AUTOSAR XML (schema 00046)
package /ComponentTypes
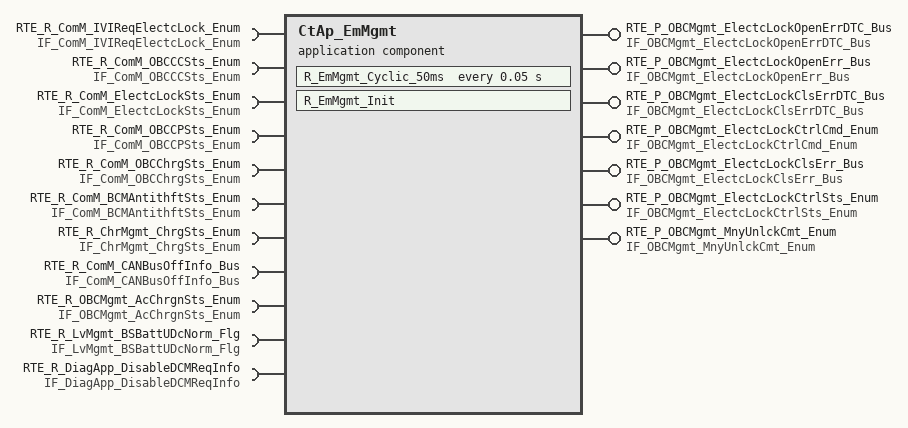
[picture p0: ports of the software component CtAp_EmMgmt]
  application sw component type CtAp_EmMgmt
    5 x provide port:
      RTE_P_OBCMgmt_ElectcLockOpenErrDTC_Bus: nonqueued-sender-com-spec{data-element=tec_OBCMgmt_ElectcLockOpenErrDTC_Bus, init-value=fields=[OBCMgmt_MonStatElectcLockOpenErrDTC:0, OBCMgmt_MonResElectcLockOpenErrDTC:0, OBCMgmt_ErrStatElectcLockOpenErrDTC:0, OBCMgmt_ErrResElectcLockOpenErrDTC:0]}, provided-interface=IF_OBCMgmt_ElectcLockOpenErrDTC_Bus
      RTE_P_OBCMgmt_ElectcLockOpenErr_Bus: nonqueued-sender-com-spec{data-element=tec_OBCMgmt_ElectcLockOpenErr_Bus, init-value=fields=[OBCMgmt_MonStatElectcLockOpenErr:0, OBCMgmt_MonResElectcLockOpenErr:0, OBCMgmt_ErrStatElectcLockOpenErr:0, OBCMgmt_ErrResElectcLockOpenErr:0]}, provided-interface=IF_OBCMgmt_ElectcLockOpenErr_Bus
      RTE_P_OBCMgmt_ElectcLockClsErrDTC_Bus: nonqueued-sender-com-spec{data-element=tec_OBCMgmt_ElectcLockClsErrDTC_Bus, init-value=fields=[OBCMgmt_MonStatElectcLockClsErrDTC:0, OBCMgmt_MonResElectcLockClsErrDTC:0, OBCMgmt_ErrStatElectcLockClsErrDTC:0, OBCMgmt_ErrResElectcLockClsErrDTC:0]}, provided-interface=IF_OBCMgmt_ElectcLockClsErrDTC_Bus
      RTE_P_OBCMgmt_ElectcLockCtrlCmd_Enum: nonqueued-sender-com-spec{data-element=tec_OBCMgmt_ElectcLockCtrlCmd_Enum, init-value=0}, provided-interface=IF_OBCMgmt_ElectcLockCtrlCmd_Enum
      RTE_P_OBCMgmt_ElectcLockClsErr_Bus: nonqueued-sender-com-spec{data-element=tec_OBCMgmt_ElectcLockClsErr_Bus, init-value=fields=[OBCMgmt_MonStatElectcLockClsErr:0, OBCMgmt_MonResElectcLockClsErr:0, OBCMgmt_ErrStatElectcLockClsErr:0, OBCMgmt_ErrResElectcLockClsErr:0]}, provided-interface=IF_OBCMgmt_ElectcLockClsErr_Bus
    require port RTE_R_ComM_IVIReqElectcLock_Enum: nonqueued-receiver-com-spec{data-element=tec_ComM_IVIReqElectcLock_Enum, filter=data-filter-type=ALWAYS, init-value=0}, required-interface=IF_ComM_IVIReqElectcLock_Enum
    provide port RTE_P_OBCMgmt_ElectcLockCtrlSts_Enum: nonqueued-sender-com-spec{data-element=tec_OBCMgmt_ElectcLockCtrlSts_Enum, init-value=0}, provided-interface=IF_OBCMgmt_ElectcLockCtrlSts_Enum
    require port RTE_R_ComM_OBCCCSts_Enum: nonqueued-receiver-com-spec{data-element=tec_ComM_OBCCCSts_Enum, filter=data-filter-type=ALWAYS, init-value=0}, required-interface=IF_ComM_OBCCCSts_Enum
    require port RTE_R_ComM_ElectcLockSts_Enum: nonqueued-receiver-com-spec{data-element=tec_ComM_ElectcLockSts_Enum, filter=data-filter-type=ALWAYS, init-value=0}, required-interface=IF_ComM_ElectcLockSts_Enum
    require port RTE_R_ComM_OBCCPSts_Enum: nonqueued-receiver-com-spec{data-element=tec_ComM_OBCCPSts_Enum, filter=data-filter-type=ALWAYS, init-value=0}, required-interface=IF_ComM_OBCCPSts_Enum
    provide port RTE_P_OBCMgmt_MnyUnlckCmt_Enum: nonqueued-sender-com-spec{data-element=tec_OBCMgmt_MnyUnlckCmt_Enum, init-value=0}, provided-interface=IF_OBCMgmt_MnyUnlckCmt_Enum
    7 x require port:
      RTE_R_ComM_OBCChrgSts_Enum: nonqueued-receiver-com-spec{data-element=tec_ComM_OBCChrgSts_Enum, filter=data-filter-type=ALWAYS, init-value=0}, required-interface=IF_ComM_OBCChrgSts_Enum
      RTE_R_ComM_BCMAntithftSts_Enum: nonqueued-receiver-com-spec{data-element=tec_ComM_BCMAntithftSts_Enum, filter=data-filter-type=ALWAYS, init-value=0}, required-interface=IF_ComM_BCMAntithftSts_Enum
      RTE_R_ChrMgmt_ChrgSts_Enum: nonqueued-receiver-com-spec{data-element=tec_ChrMgmt_ChrgSts_Enum, filter=data-filter-type=ALWAYS, init-value=0}, required-interface=IF_ChrMgmt_ChrgSts_Enum
      RTE_R_ComM_CANBusOffInfo_Bus: required-interface=IF_ComM_CANBusOffInfo_Bus
        required-com-specs:
          data-element=tec_ComM_EPTCANBusOffInfo_Bus, filter=data-filter-type=ALWAYS, init-value=fields=[ComM_MonStatEPTCANBusOffInfo:0, ComM_MonResEPTCANBusOffInfo:0, ComM_ErrStatEPTCANBusOffInfo:0, ComM_ErrResEPTCANBusOffInfo:0]
          data-element=tec_ComM_CHCANBusOffInfo_Bus, filter=data-filter-type=ALWAYS, init-value=fields=[ComM_MonStatCHCANBusOffInfo:0, ComM_MonResCHCANBusOffInfo:0, ComM_ErrStatCHCANBusOffInfo:0, ComM_ErrResCHCANBusOffInfo:0]
          data-element=tec_ComM_EPTCANBusOffDTCInfo_Bus, filter=data-filter-type=ALWAYS, init-value=fields=[ComM_MonStatEPTCANBusOffDTCInfo:0, ComM_MonResEPTCANBusOffDTCInfo:0, ComM_ErrStatEPTCANBusOffDTCInfo:0, ComM_ErrResEPTCANBusOffDTCInfo:0]
          data-element=tec_ComM_CHCANBusOffDTCInfo_Bus, filter=data-filter-type=ALWAYS, init-value=fields=[ComM_MonStatCHCANBusOffDTCInfo:0, ComM_MonResCHCANBusOffDTCInfo:0, ComM_ErrStatCHCANBusOffDTCInfo:0, ComM_ErrResCHCANBusOffDTCInfo:0]
          data-element=tec_ComM_DCCANBusOffDTCInfo_Bus, init-value=fields=[ComM_MonStatDCCANDTCBusOffInfo:0, ComM_MonResDCCANDTCBusOffInfo:0, ComM_ErrStatDCCANDTCBusOffInfo:0, ComM_ErrResDCCANDTCBusOffInfo:0]
          data-element=tec_ComM_DCCANBusOffInfo_Bus, init-value=fields=[ComM_MonStatDCCANBusOffInfo:0, ComM_MonResDCCANBusOffInfo:0, ComM_ErrStatDCCANBusOffInfo:0, ComM_ErrResDCCANBusOffInfo:0]
      RTE_R_OBCMgmt_AcChrgnSts_Enum: nonqueued-receiver-com-spec{data-element=tec_OBCMgmt_AcChrgnSts_Enum, filter=data-filter-type=ALWAYS, init-value=0}, required-interface=IF_OBCMgmt_AcChrgnSts_Enum
      RTE_R_LvMgmt_BSBattUDcNorm_Flg: nonqueued-receiver-com-spec{data-element=tec_LvMgmt_BSBattUDcNorm_Flg, filter=data-filter-type=ALWAYS, init-value=0}, required-interface=IF_LvMgmt_BSBattUDcNorm_Flg
      RTE_R_DiagApp_DisableDCMReqInfo: nonqueued-receiver-com-spec{data-element=tec_DiagApp_DisableDCMReqInfo, filter=data-filter-type=ALWAYS, init-value=0}, required-interface=IF_DiagApp_DisableDCMReqInfo
    behavior CtAp_EmMgmt_InternalBehavior
      timing event TMT_R_EmMgmt_Cyclic_50ms: start-on-event=R_EmMgmt_Cyclic_50ms, period=0.05
      init event CtAp_EmMgmt_InitEvent: start-on-event=R_EmMgmt_Init
      runnable R_EmMgmt_Cyclic_50ms
        data-receive-point-by-arguments:
          11 x access:
            REC_RTE_R_ChrMgmt_ChrgSts_Enum_tec_ChrMgmt_ChrgSts_Enum: accessed-variable=RTE_R_ChrMgmt_ChrgSts_Enum.tec_ChrMgmt_ChrgSts_Enum
            REC_RTE_R_ComM_BCMAntithftSts_Enum_tec_ComM_BCMAntithftSts_Enum: accessed-variable=RTE_R_ComM_BCMAntithftSts_Enum.tec_ComM_BCMAntithftSts_Enum
            REC_RTE_R_ComM_CANBusOffInfo_Bus_tec_ComM_EPTCANBusOffInfo_Bus: accessed-variable=RTE_R_ComM_CANBusOffInfo_Bus.tec_ComM_EPTCANBusOffInfo_Bus
            REC_RTE_R_ComM_ElectcLockSts_Enum_tec_ComM_ElectcLockSts_Enum: accessed-variable=RTE_R_ComM_ElectcLockSts_Enum.tec_ComM_ElectcLockSts_Enum
            REC_RTE_R_ComM_IVIReqElectcLock_Enum_tec_ComM_IVIReqElectcLock_Enum: accessed-variable=RTE_R_ComM_IVIReqElectcLock_Enum.tec_ComM_IVIReqElectcLock_Enum
            REC_RTE_R_ComM_OBCCCSts_Enum_tec_ComM_OBCCCSts_Enum: accessed-variable=RTE_R_ComM_OBCCCSts_Enum.tec_ComM_OBCCCSts_Enum
            REC_RTE_R_ComM_OBCCPSts_Enum_tec_ComM_OBCCPSts_Enum: accessed-variable=RTE_R_ComM_OBCCPSts_Enum.tec_ComM_OBCCPSts_Enum
            REC_RTE_R_ComM_OBCChrgSts_Enum_tec_ComM_OBCChrgSts_Enum: accessed-variable=RTE_R_ComM_OBCChrgSts_Enum.tec_ComM_OBCChrgSts_Enum
            REC_RTE_R_OBCMgmt_AcChrgnSts_Enum_tec_OBCMgmt_AcChrgnSts_Enum: accessed-variable=RTE_R_OBCMgmt_AcChrgnSts_Enum.tec_OBCMgmt_AcChrgnSts_Enum
            REC_RTE_R_LvMgmt_BSBattUDcNorm_Flg_tec_LvMgmt_BSBattUDcNorm_Flg: accessed-variable=RTE_R_LvMgmt_BSBattUDcNorm_Flg.tec_LvMgmt_BSBattUDcNorm_Flg
            REC_RTE_R_DiagApp_DisableDCMReqInfo_tec_DiagApp_DisableDCMReqInfo: accessed-variable=RTE_R_DiagApp_DisableDCMReqInfo.tec_DiagApp_DisableDCMReqInfo
        data-send-points:
          7 x access:
            SEND_RTE_P_OBCMgmt_ElectcLockClsErrDTC_Bus_tec_OBCMgmt_ElectcLockClsErrDTC_Bus: accessed-variable=RTE_P_OBCMgmt_ElectcLockClsErrDTC_Bus.tec_OBCMgmt_ElectcLockClsErrDTC_Bus
            SEND_RTE_P_OBCMgmt_ElectcLockClsErr_Bus_tec_OBCMgmt_ElectcLockClsErr_Bus: accessed-variable=RTE_P_OBCMgmt_ElectcLockClsErr_Bus.tec_OBCMgmt_ElectcLockClsErr_Bus
            SEND_RTE_P_OBCMgmt_ElectcLockCtrlCmd_Enum_tec_OBCMgmt_ElectcLockCtrlCmd_Enum: accessed-variable=RTE_P_OBCMgmt_ElectcLockCtrlCmd_Enum.tec_OBCMgmt_ElectcLockCtrlCmd_Enum
            SEND_RTE_P_OBCMgmt_ElectcLockCtrlSts_Enum_tec_OBCMgmt_ElectcLockCtrlSts_Enum: accessed-variable=RTE_P_OBCMgmt_ElectcLockCtrlSts_Enum.tec_OBCMgmt_ElectcLockCtrlSts_Enum
            SEND_RTE_P_OBCMgmt_ElectcLockOpenErrDTC_Bus_tec_OBCMgmt_ElectcLockOpenErrDTC_Bus: accessed-variable=RTE_P_OBCMgmt_ElectcLockOpenErrDTC_Bus.tec_OBCMgmt_ElectcLockOpenErrDTC_Bus
            SEND_RTE_P_OBCMgmt_ElectcLockOpenErr_Bus_tec_OBCMgmt_ElectcLockOpenErr_Bus: accessed-variable=RTE_P_OBCMgmt_ElectcLockOpenErr_Bus.tec_OBCMgmt_ElectcLockOpenErr_Bus
            SEND_RTE_P_OBCMgmt_MnyUnlckCmt_Enum_tec_OBCMgmt_MnyUnlckCmt_Enum: accessed-variable=RTE_P_OBCMgmt_MnyUnlckCmt_Enum.tec_OBCMgmt_MnyUnlckCmt_Enum
      runnable R_EmMgmt_Init
  swc implementation CtAp_EmMgmt_Implementation: behavior=CtAp_EmMgmt_InternalBehavior
